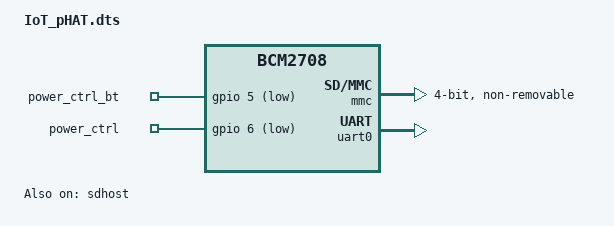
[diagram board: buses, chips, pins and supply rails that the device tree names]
/dts-v1/;
/plugin/;

/{
	compatible = "brcm,bcm2708";

	fragment@0 {
		target = <&sdhost>;
		frag0: __overlay__ {
			brcm,overclock-50 = <0>;
			brcm,pio-limit = <1>;
			brcm,debug-flags = <0>;
			status = "okay";
		};
	};

	fragment@1 {
		target = <&mmc>;
		__overlay__ {
			status = "disabled";
		};
	};

	fragment@3 {
		target = <&mmc>;
		sdio_mmc: __overlay__ {
			pinctrl-names = "default";
			pinctrl-0 = <&sdio_pins>;
			non-removable;
			bus-width = <4>;
			brcm,overclock-50 = <0>;
			status = "okay";
		};
	};

	fragment@4 {
		target = <&gpio>;
		__overlay__ {
			sdio_pins: sdio_pins {
				brcm,pins = <22 23 24 25 26 27>;
				brcm,function = <7 7 7 7 7 7>;
				brcm,pull = <0 2 2 2 2 2>;
			};
		};
	};

	fragment@5 {
		target-path = "/";
		__overlay__ {
			power_ctrl_bt: power_ctrl_bt {
				compatible = "gpio-poweroff";
				gpios = <&gpio 5 1>;
				force;
			};
		};
	};

	fragment@6 {
		target-path = "/";
		__overlay__ {
			power_ctrl: power_ctrl {
				compatible = "gpio-poweroff";
				gpios = <&gpio 6 1>;
				force;
			};
		};
	};

	fragment@7 {
		target = <&gpio>;
		__overlay__ {
			power_ctrl_pins: power_ctrl_pins {
				brcm,pins = <5 6>;
				brcm,function = <1 1>;
			};
		};
	};

	fragment@8 {
		target = <&gpio>;
		__overlay__ {
			bt_pins: bt_pins {
				brcm,pins = <5>;
				brcm,function = <1>;
				brcm,pull = <2>;
			};
		}; 
	};

	fragment@9 {
		target-path = "/soc";
		__overlay__ {
			iothat {
				pinctrl-names = "default";
				pinctrl-0 = <&bt_pins>;
				status = "okay";
			};
		};
	};

	fragment@10 {
		target = <&uart0>;
		__overlay__ {
			pinctrl-names = "default";
			pinctrl-0 = <&uart0_pins>;
			status = "okay";
		};
	};

	fragment@11 {
		target = <&gpio>;
		__overlay__ {
			uart0_pins: uart0_pins {
				brcm,pins = <14 15>;
				brcm,function = <4>;
				brcm,pull = <0 2>;
			};
		};
	};

	fragment@12 {
		target-path = "/chosen";
		__overlay__ {
			bootargs = "8250.nr_uarts=1";
		};
	};

	fragment@13 {
		target-path = "/aliases";
		__overlay__ {
			serial1 = "/soc/uart@7e201000";
			serial0 = "/soc/uart@7e215040";
		};
	};
};
